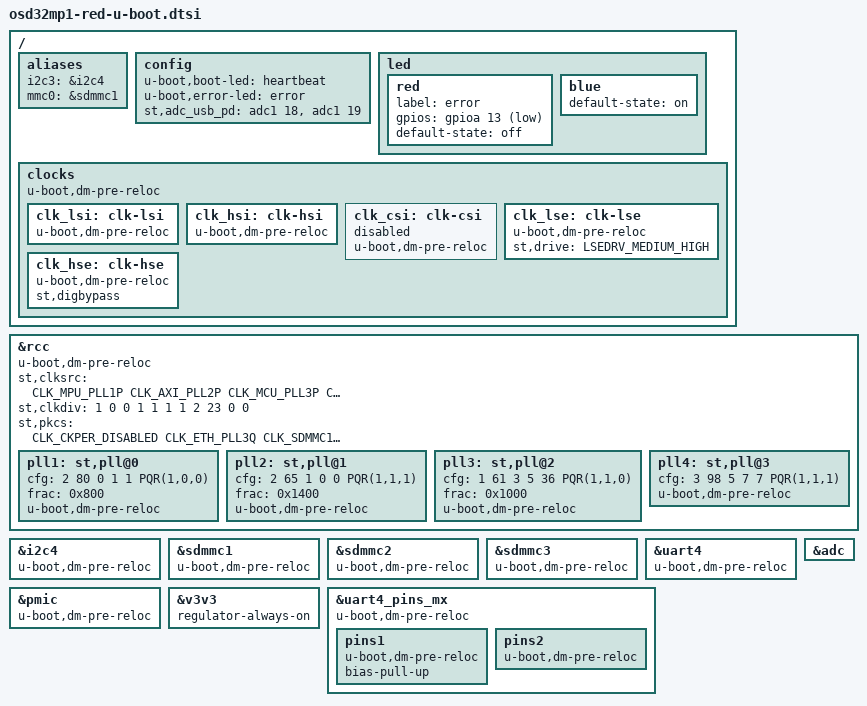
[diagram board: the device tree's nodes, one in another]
/* SPDX-License-Identifier: GPL-2.0+ OR BSD-3-Clause*/
/*
 * Copyright (C) 2020, STMicroelectronics - All Rights Reserved
 * Author: STM32CubeMX code generation for STMicroelectronics.
 */

/* For more information on Device Tree configuration, please refer to
 * https://wiki.st.com/stm32mpu/wiki/Category:Device_tree_configuration
 */

#include <dt-bindings/clock/stm32mp1-clksrc.h>
#include "stm32mp15-osd32mp1-ddr3-1x4Gb-1066-binG.dtsi"

#include "stm32mp157-u-boot.dtsi"
#include "stm32mp15-ddr.dtsi"




/ {


	aliases {
		i2c3 = &i2c4;
		mmc0 = &sdmmc1;					//orig
		//mmc0 = &sdmmc2;						//custom
	};
	config {
		u-boot,boot-led = "heartbeat";
		u-boot,error-led = "error";
		st,adc_usb_pd = <&adc1 18>, <&adc1 19>;
		//st,fastboot-gpios = <&gpioa 13 GPIO_ACTIVE_LOW>;	//custom
		//st,stm32prog-gpios = <&gpioa 14 GPIO_ACTIVE_LOW>;	//custom
	};
	led {
		red {
			label = "error";
			gpios = <&gpioa 13 GPIO_ACTIVE_LOW>;
			default-state = "off";
			status = "okay";
		};

		blue {
			default-state = "on";
		};
	};


	clocks {
		u-boot,dm-pre-reloc;




		clk_lsi: clk-lsi {
			u-boot,dm-pre-reloc;



		};

		clk_hsi: clk-hsi {
			u-boot,dm-pre-reloc;



		};

		clk_csi: clk-csi {
			u-boot,dm-pre-reloc;
			status = "disabled";



		};

		clk_lse: clk-lse {
			u-boot,dm-pre-reloc;
			st,drive = < LSEDRV_MEDIUM_HIGH >;



		};

		clk_hse: clk-hse {
			u-boot,dm-pre-reloc;
			st,digbypass;



		};
	};

}; /*root*/

&rcc {
	u-boot,dm-pre-reloc;
	st,clksrc = <
		CLK_MPU_PLL1P
		CLK_AXI_PLL2P
		CLK_MCU_PLL3P
		CLK_PLL12_HSE
		CLK_PLL3_HSE
		CLK_PLL4_HSE
		CLK_RTC_LSE
		CLK_MCO1_DISABLED
		CLK_MCO2_DISABLED
	>;
	st,clkdiv = <
		1 		/*MPU*/
		0 		/*AXI*/
		0 		/*MCU*/
		1 		/*APB1*/
		1 		/*APB2*/
		1 		/*APB3*/
		1 		/*APB4*/
		2 		/*APB5*/
		23 		/*RTC*/
		0 		/*MCO1*/
		0 		/*MCO2*/
	>;
	st,pkcs = <
		CLK_CKPER_DISABLED
		CLK_ETH_PLL3Q
		CLK_SDMMC12_PLL4P
		CLK_DSI_DSIPLL
		CLK_STGEN_HSE
		CLK_USBPHY_DISABLED
		CLK_SPI2S1_DISABLED
		CLK_SPI2S23_PLL3Q
		CLK_SPI45_DISABLED
		CLK_SPI6_DISABLED
		CLK_I2C46_HSI
		CLK_SDMMC3_PLL4P
		CLK_ADC_DISABLED
		CLK_CEC_DISABLED
		CLK_I2C12_HSI
		CLK_I2C35_DISABLED
		CLK_UART1_DISABLED
		CLK_UART24_HSI
		CLK_UART35_DISABLED
		CLK_UART6_DISABLED
		CLK_UART78_DISABLED
		CLK_SPDIF_DISABLED
		CLK_SAI2_CKPER
		CLK_SAI2_DISABLED
		CLK_SAI3_DISABLED
		CLK_SAI4_DISABLED
		CLK_RNG1_LSI
		CLK_LPTIM1_DISABLED
		CLK_LPTIM23_DISABLED
		CLK_LPTIM45_DISABLED
	>;
	pll1:st,pll@0 {
		cfg = < 2 80 0 1 1 PQR(1,0,0) >;
		frac = < 0x800>;
		u-boot,dm-pre-reloc;
	};
	pll2:st,pll@1 {
		cfg = < 2 65 1 0 0 PQR(1,1,1) >;
		frac = < 0x1400>;
		u-boot,dm-pre-reloc;
	};
	pll3:st,pll@2 {
		cfg = < 1 61 3 5 36 PQR(1,1,0) >;
		frac = < 0x1000 >;
		u-boot,dm-pre-reloc;
	};
	pll4:st,pll@3 {
		cfg = < 3 98 5 7 7 PQR(1,1,1) >;
		u-boot,dm-pre-reloc;
	};
};

&i2c4{
	u-boot,dm-pre-reloc;



};

&rcc{
	u-boot,dm-pre-reloc;



};

&sdmmc1{
	u-boot,dm-pre-reloc;



};

&sdmmc2{
	u-boot,dm-pre-reloc;



};

&sdmmc3{
	u-boot,dm-pre-reloc;



};

&uart4{
	u-boot,dm-pre-reloc;



};


&pmic {
	u-boot,dm-pre-reloc;
};

&v3v3 {
	regulator-always-on;
};

&uart4_pins_mx {
	u-boot,dm-pre-reloc;
	pins1 {
		u-boot,dm-pre-reloc;
		/* pull-up on rx to avoid floating level */
		bias-pull-up;
	};
	pins2 {
		u-boot,dm-pre-reloc;
	};
};

&adc {
	status = "okay";
};


